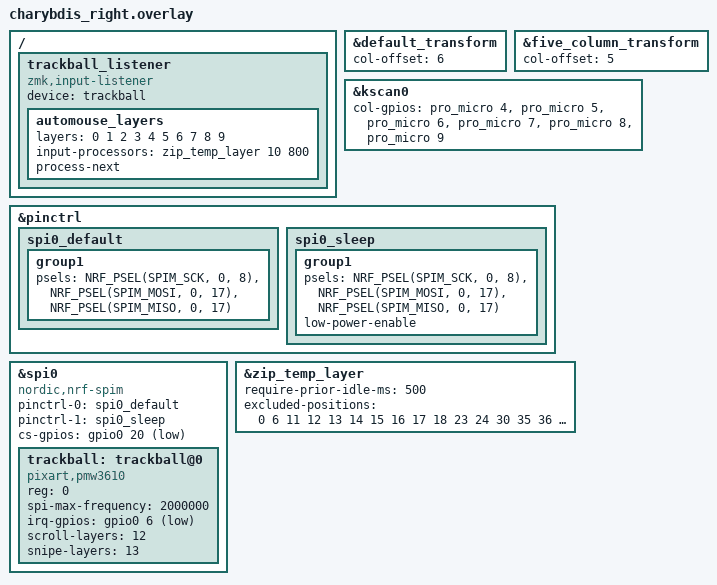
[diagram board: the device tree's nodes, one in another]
/*
 * Copyright (c) 2020 ZMK Contributors
 *
 * SPDX-License-Identifier: MIT
 */
 
#include "charybdis.dtsi"
#include <input/processors.dtsi>

&default_transform {
	col-offset = <6>;
};

&five_column_transform {
	col-offset = <5>;
};

&kscan0 {
	col-gpios
		= <&pro_micro 4 GPIO_ACTIVE_HIGH>
		, <&pro_micro 5 GPIO_ACTIVE_HIGH>
		, <&pro_micro 6 GPIO_ACTIVE_HIGH>
		, <&pro_micro 7 GPIO_ACTIVE_HIGH>
		, <&pro_micro 8 GPIO_ACTIVE_HIGH>
		, <&pro_micro 9 GPIO_ACTIVE_HIGH>
		;
};

&pinctrl {
    spi0_default: spi0_default {
        group1 {
            psels = <NRF_PSEL(SPIM_SCK, 0, 8)>,
                <NRF_PSEL(SPIM_MOSI, 0, 17)>,
                <NRF_PSEL(SPIM_MISO, 0, 17)>;
        };
    };

    spi0_sleep: spi0_sleep {
        group1 {
            psels = <NRF_PSEL(SPIM_SCK, 0, 8)>,
                <NRF_PSEL(SPIM_MOSI, 0, 17)>,
                <NRF_PSEL(SPIM_MISO, 0, 17)>;
            low-power-enable;
        };
    };
};

&spi0 {
    status = "okay";
    compatible = "nordic,nrf-spim";
    pinctrl-0 = <&spi0_default>;
    pinctrl-1 = <&spi0_sleep>;
    pinctrl-names = "default", "sleep";
    cs-gpios = <&gpio0 20 GPIO_ACTIVE_LOW>;

    trackball: trackball@0 {
        status = "okay";
        compatible = "pixart,pmw3610";
        reg = <0>;
        spi-max-frequency = <2000000>;
        irq-gpios = <&gpio0 6 (GPIO_ACTIVE_LOW | GPIO_PULL_UP)>;
         /*   optional features   */
        scroll-layers = <12>;
        // automouse-layer = <10>;
        snipe-layers = <13>;
    };
};

&zip_temp_layer {
    require-prior-idle-ms = <500>;
    //  0  x o o o o o  5   6  x o o o o x  11
    // 12  x x x x x x  17 18  x o o o o x  23
    // 24  x o o o o o  29 30  x o o o o x  35
    // 36        x x x  38 39  o o o        41
    excluded-positions = <0 6 11 12 13 14 15 16 17 18 23 24 30 35 36 37 38>;
};

/ {
  trackball_listener {
    compatible = "zmk,input-listener";
    device = <&trackball>;

    automouse_layers {
        layers = <0 1 2 3 4 5 6 7 8 9>;
        input-processors = <&zip_temp_layer 10 800>;
        process-next;
    };
  };
};
